# HC32K118 register map
File version: 1.0
CPU: CM0+ r0p1, little endian, no MPU, no FPU, 2 interrupt priority bits
Registers are 32-bit, read-write, reset 0x0 unless marked. A register's access mark holds for its fields unless they carry their own. Offsets are from the block's base; [hi:lo] are bit positions; {n}, {i} and the like mark numbered series; 'fields as' and 'values as' point back to an identical list.

## I2C
Base 0x40004800
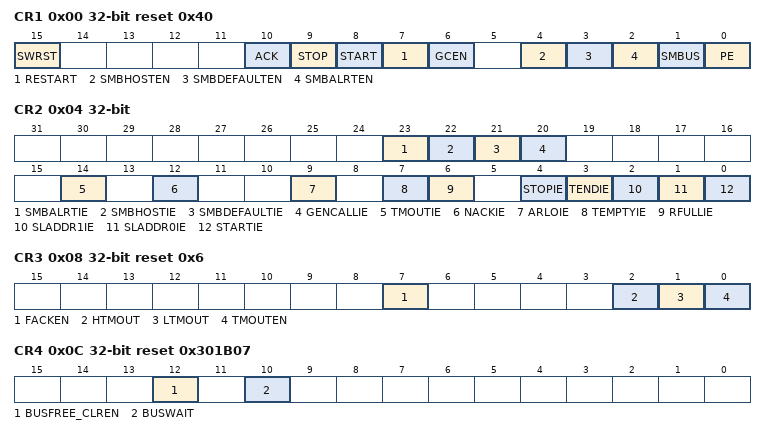
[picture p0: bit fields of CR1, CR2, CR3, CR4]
0x00 CR1 reset 0x40
  [15] SWRST, [10] ACK, [9] STOP, [8] START, [7] RESTART, [6] GCEN, [4] SMBHOSTEN, [3] SMBDEFAULTEN, [2] SMBALRTEN, [1] SMBUS, [0] PE
0x04 CR2
  [23] SMBALRTIE, [22] SMBHOSTIE, [21] SMBDEFAULTIE, [20] GENCALLIE, [14] TMOUTIE, [12] NACKIE, [9] ARLOIE, [7] TEMPTYIE, [6] RFULLIE, [4] STOPIE, [3] TENDIE, [2] SLADDR1IE, [1] SLADDR0IE, [0] STARTIE
0x08 CR3 reset 0x6
  [7] FACKEN, [2] HTMOUT, [1] LTMOUT, [0] TMOUTEN
0x0C CR4 reset 0x301B07
  [12] BUSFREE_CLREN, [10] BUSWAIT
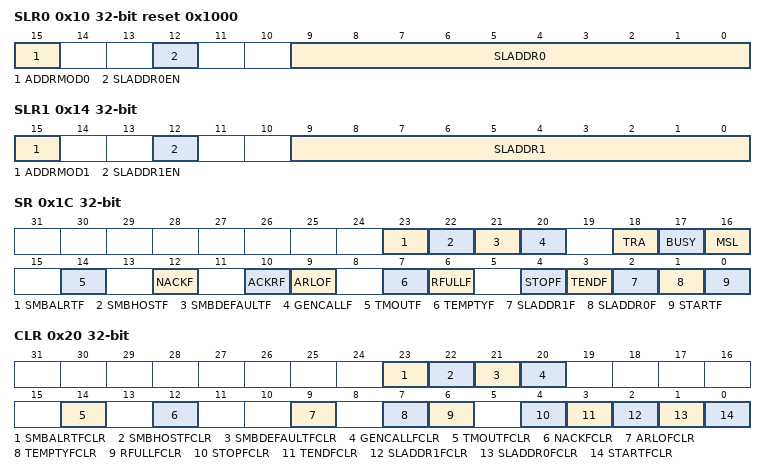
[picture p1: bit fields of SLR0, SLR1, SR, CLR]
0x10 SLR0 reset 0x1000
  [15] ADDRMOD0, [12] SLADDR0EN, [9:0] SLADDR0
0x14 SLR1
  [15] ADDRMOD1, [12] SLADDR1EN, [9:0] SLADDR1
0x1C SR
  [23] SMBALRTF ro, [22] SMBHOSTF ro, [21] SMBDEFAULTF ro, [20] GENCALLF ro, [18] TRA, [17] BUSY ro, [16] MSL, [14] TMOUTF ro, [12] NACKF ro, [10] ACKRF ro, [9] ARLOF ro, [7] TEMPTYF ro, [6] RFULLF ro, [4] STOPF ro, [3] TENDF ro, [2] SLADDR1F ro, [1] SLADDR0F ro, [0] STARTF ro
0x20 CLR wo
  [23] SMBALRTFCLR, [22] SMBHOSTFCLR, [21] SMBDEFAULTFCLR, [20] GENCALLFCLR, [14] TMOUTFCLR, [12] NACKFCLR, [9] ARLOFCLR, [7] TEMPTYFCLR, [6] RFULLFCLR, [4] STOPFCLR, [3] TENDFCLR, [2] SLADDR1FCLR, [1] SLADDR0FCLR, [0] STARTFCLR
0x24 DTR 8-bit reset 0xFF
0x28 DRR 8-bit
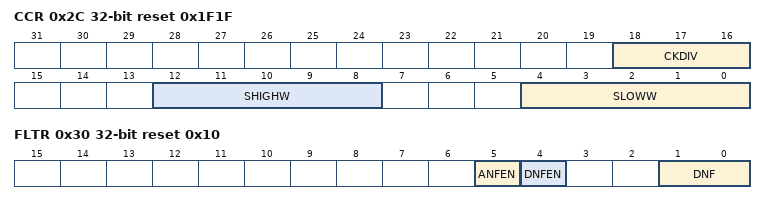
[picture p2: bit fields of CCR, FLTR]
0x2C CCR reset 0x1F1F
  [18:16] CKDIV, [12:8] SHIGHW, [4:0] SLOWW
0x30 FLTR reset 0x10
  [5] ANFEN, [4] DNFEN, [1:0] DNF

## ICGA
Base 0x01000A00
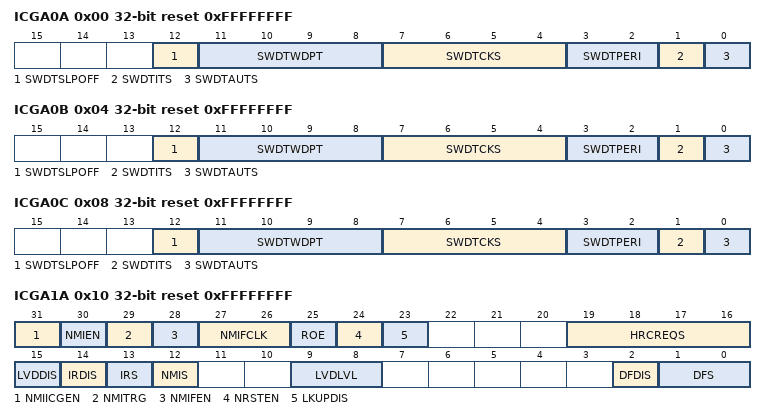
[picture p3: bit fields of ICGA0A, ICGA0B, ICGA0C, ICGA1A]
0x00 ICGA0A ro reset 0xFFFFFFFF
  [12] SWDTSLPOFF, [11:8] SWDTWDPT, [7:4] SWDTCKS, [3:2] SWDTPERI, [1] SWDTITS, [0] SWDTAUTS
0x04 ICGA0B ro reset 0xFFFFFFFF
  fields as ICGA0A
0x08 ICGA0C ro reset 0xFFFFFFFF
  fields as ICGA0A
0x10 ICGA1A ro reset 0xFFFFFFFF
  [31] NMIICGEN, [30] NMIEN, [29] NMITRG, [28] NMIFEN, [27:26] NMIFCLK, [25] ROE, [24] NRSTEN, [23] LKUPDIS, [19:16] HRCREQS, [15] LVDDIS, [14] IRDIS, [13] IRS, [12] NMIS, [9:8] LVDLVL, [2] DFDIS, [1:0] DFS
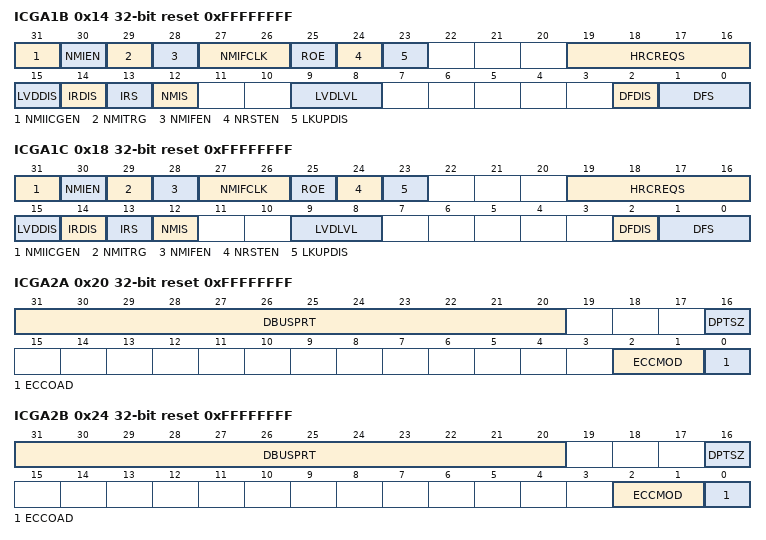
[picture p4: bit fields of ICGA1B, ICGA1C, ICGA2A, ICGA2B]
0x14 ICGA1B ro reset 0xFFFFFFFF
  fields as ICGA1A
0x18 ICGA1C ro reset 0xFFFFFFFF
  fields as ICGA1A
0x20 ICGA2A ro reset 0xFFFFFFFF
  [31:20] DBUSPRT, [16] DPTSZ, [2:1] ECCMOD, [0] ECCOAD
0x24 ICGA2B ro reset 0xFFFFFFFF
  [31:20] DBUSPRT, [16] DPTSZ, [2:1] ECCMOD, [0] ECCOAD
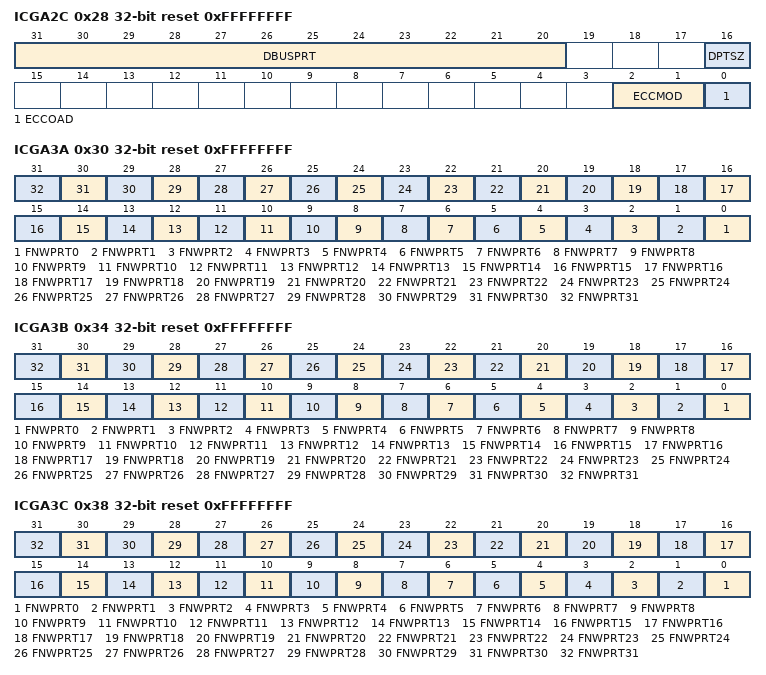
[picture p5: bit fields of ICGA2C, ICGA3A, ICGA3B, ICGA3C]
0x28 ICGA2C ro reset 0xFFFFFFFF
  [31:20] DBUSPRT, [16] DPTSZ, [2:1] ECCMOD, [0] ECCOAD
0x30 ICGA3A ro reset 0xFFFFFFFF
  [n] FNWPRT{n} (n=0..31)
0x34 ICGA3B ro reset 0xFFFFFFFF
  [n] FNWPRT{n} (n=0..31)
0x38 ICGA3C ro reset 0xFFFFFFFF
  [n] FNWPRT{n} (n=0..31)
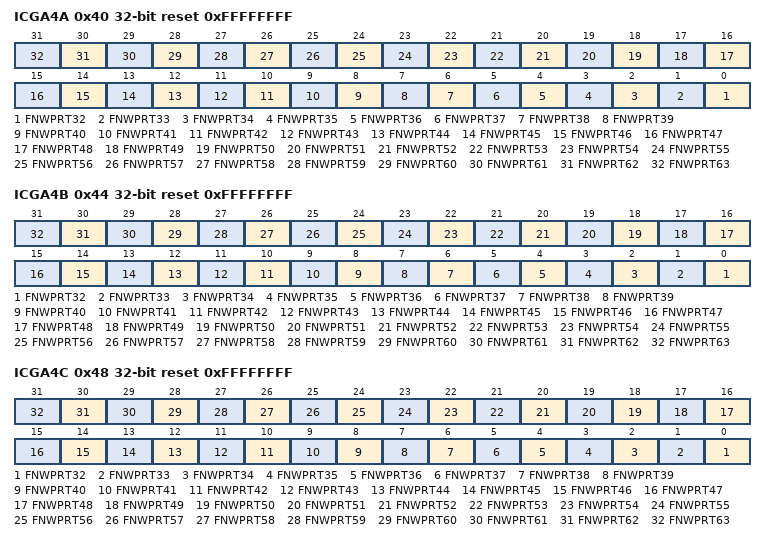
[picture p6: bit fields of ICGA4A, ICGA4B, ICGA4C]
0x40 ICGA4A ro reset 0xFFFFFFFF
  [n-32] FNWPRT{n} (n=32..63)
0x44 ICGA4B ro reset 0xFFFFFFFF
  [n-32] FNWPRT{n} (n=32..63)
0x48 ICGA4C ro reset 0xFFFFFFFF
  [n-32] FNWPRT{n} (n=32..63)

## ICGB
Base 0x40017800
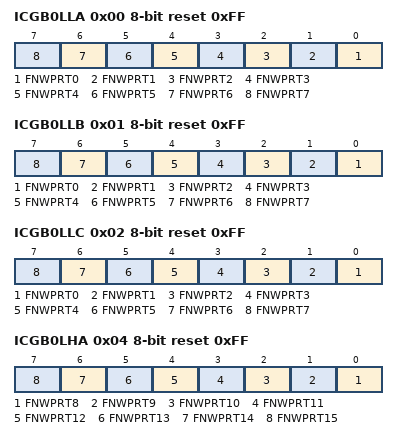
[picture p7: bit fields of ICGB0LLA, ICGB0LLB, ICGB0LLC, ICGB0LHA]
0x00 ICGB0LLA 8-bit ro reset 0xFF
  [n] FNWPRT{n} (n=0..7)
0x01 ICGB0LLB 8-bit ro reset 0xFF
  [n] FNWPRT{n} (n=0..7)
0x02 ICGB0LLC 8-bit ro reset 0xFF
  [n] FNWPRT{n} (n=0..7)
0x04 ICGB0LHA 8-bit ro reset 0xFF
  [n-8] FNWPRT{n} (n=8..15)
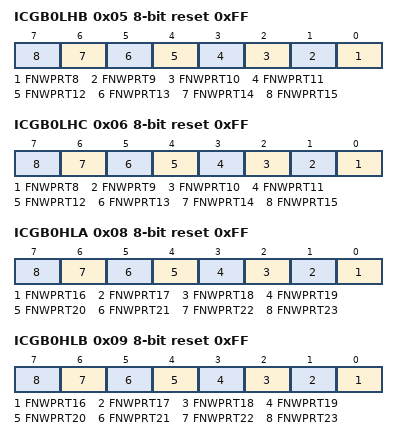
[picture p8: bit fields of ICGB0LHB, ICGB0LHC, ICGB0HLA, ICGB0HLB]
0x05 ICGB0LHB 8-bit ro reset 0xFF
  [n-8] FNWPRT{n} (n=8..15)
0x06 ICGB0LHC 8-bit ro reset 0xFF
  [n-8] FNWPRT{n} (n=8..15)
0x08 ICGB0HLA 8-bit ro reset 0xFF
  [n-16] FNWPRT{n} (n=16..23)
0x09 ICGB0HLB 8-bit ro reset 0xFF
  [n-16] FNWPRT{n} (n=16..23)
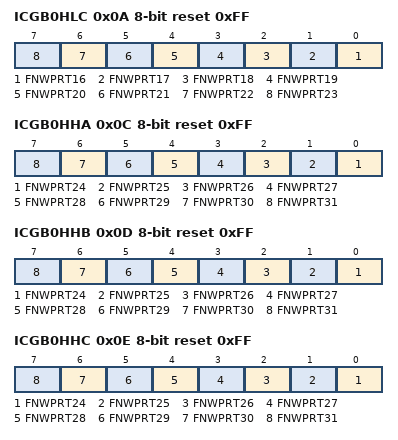
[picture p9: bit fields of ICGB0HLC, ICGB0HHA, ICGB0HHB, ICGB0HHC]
0x0A ICGB0HLC 8-bit ro reset 0xFF
  [n-16] FNWPRT{n} (n=16..23)
0x0C ICGB0HHA 8-bit ro reset 0xFF
  [n-24] FNWPRT{n} (n=24..31)
0x0D ICGB0HHB 8-bit ro reset 0xFF
  [n-24] FNWPRT{n} (n=24..31)
0x0E ICGB0HHC 8-bit ro reset 0xFF
  [n-24] FNWPRT{n} (n=24..31)
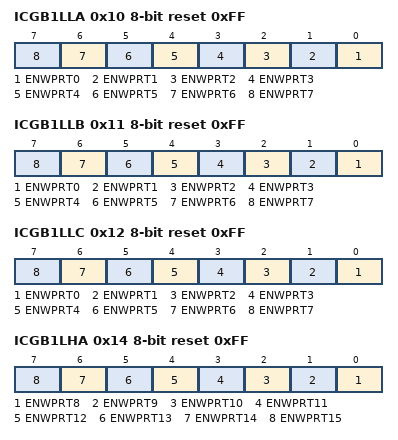
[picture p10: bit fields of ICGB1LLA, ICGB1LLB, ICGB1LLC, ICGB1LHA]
0x10 ICGB1LLA 8-bit ro reset 0xFF
  [n] ENWPRT{n} (n=0..7)
0x11 ICGB1LLB 8-bit ro reset 0xFF
  [n] ENWPRT{n} (n=0..7)
0x12 ICGB1LLC 8-bit ro reset 0xFF
  [n] ENWPRT{n} (n=0..7)
0x14 ICGB1LHA 8-bit ro reset 0xFF
  [n-8] ENWPRT{n} (n=8..15)
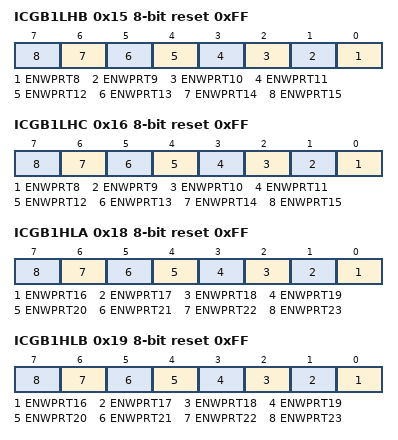
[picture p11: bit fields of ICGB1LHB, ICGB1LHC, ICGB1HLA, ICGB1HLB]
0x15 ICGB1LHB 8-bit ro reset 0xFF
  [n-8] ENWPRT{n} (n=8..15)
0x16 ICGB1LHC 8-bit ro reset 0xFF
  [n-8] ENWPRT{n} (n=8..15)
0x18 ICGB1HLA 8-bit ro reset 0xFF
  [n-16] ENWPRT{n} (n=16..23)
0x19 ICGB1HLB 8-bit ro reset 0xFF
  [n-16] ENWPRT{n} (n=16..23)
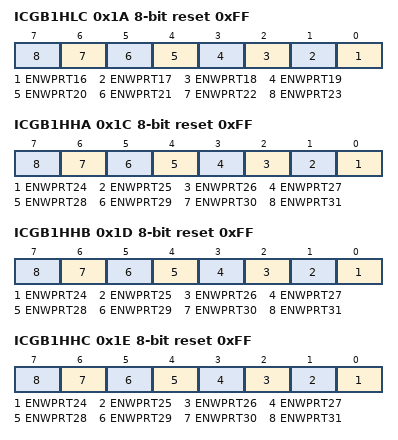
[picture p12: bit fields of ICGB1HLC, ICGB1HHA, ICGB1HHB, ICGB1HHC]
0x1A ICGB1HLC 8-bit ro reset 0xFF
  [n-16] ENWPRT{n} (n=16..23)
0x1C ICGB1HHA 8-bit ro reset 0xFF
  [n-24] ENWPRT{n} (n=24..31)
0x1D ICGB1HHB 8-bit ro reset 0xFF
  [n-24] ENWPRT{n} (n=24..31)
0x1E ICGB1HHC 8-bit ro reset 0xFF
  [n-24] ENWPRT{n} (n=24..31)
